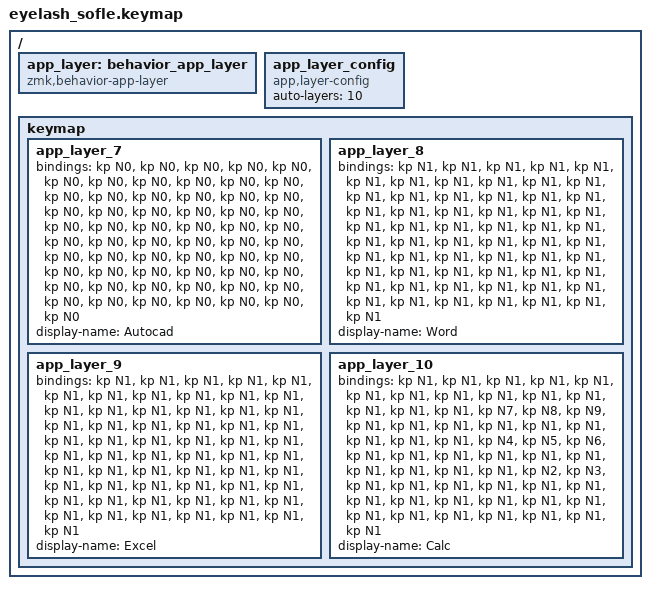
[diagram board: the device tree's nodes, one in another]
// =============================================================================
// SELENIUM KEYMAP — Main Configuration
// =============================================================================
//
// This file defines the keyboard layout using the zmk-config-selenium module.
// The SELENIUM_KEYMAP_BINDINGS macro provides a template for the base layer,
// and selenium.keymap fills in the home-row mods, layer-taps, and combos.
//
// See: https://github.com/keebs34/zmk-config-selenium/blob/main/include/selenium/settings.h
//

// =============================================================================
// LAYOUT OPTIONS (from zmk-config-selenium)
// =============================================================================

// Ergonomic column-staggered layout (Sofle/Corne style)
#define KB_LAYOUT_ERGOL

// macOS keybindings (Cmd instead of Ctrl for shortcuts)
#define MACOS

// Home-row mods: letter keys become modifiers when held
#define HT_HOME_ROW_MODS

// Shift is handled by home-row mods on E/R keys
#define HRM_SHIFT

// Pinky modifiers require holding (not tap)
#define PINKY_MOD_HOLD

// Short tapping term: 250ms to distinguish tap vs hold
#define SHORT_TAPPING_TERM 250

// =============================================================================
// BASE LAYOUT MACRO
// =============================================================================
//
// Defines all 5 rows of the keyboard:
//   Row 1 (top):       numbers, ESC, arrows, BACKSPACE
//   Row 2 (home):      LOUT1/LROW1 = outer/home keys, filled by selenium.keymap
//   Row 3 (bottom):    LOUT2/LROW2 = outer/home keys, filled by selenium.keymap
//   Row 4 (alpha low): LOUT3/LROW3 = outer/home keys, filled by selenium.keymap
//   Row 5 (thumbs):    LT1/LT2/LT3 = left thumb keys, RT1/RT2/RT3 = right thumb keys
//
// Parameters:
//   LOUT/LROW/RROW/ROUT: Injected by selenium.keymap (home-row mods, layer-taps)
//   LT1/LT2/LT3/RT3/RT2/RT1: Thumb cluster keys (layer-taps, modifiers, app_layer)
//
// &app_layer on the left thumb toggles the current app layer:
//   1 press = activate the layer stored in memory (from Mac's command)
//   2 presses = deactivate (return to base layer)
//
#define SELENIUM_KEYMAP_BINDINGS(LOUT1,  LROW1,  RROW1,  ROUT1, \
                                 LOUT2,  LROW2,  RROW2,  ROUT2, \
                                 LOUT3,  LROW3,  RROW3,  ROUT3, \
                                 LT1, LT2, LT3,  RT3, RT2, RT1) \
    &kp ESC &kp N1 &kp N2 &kp N3 &kp N4 &kp N5  &kp UP_ARROW &kp N6 &kp N7 &kp N8 &kp N9 &kp N0 &kp BACKSPACE \
    LOUT1   LROW1                               &kp DOWN_ARROW                           RROW1  ROUT1         \
    LOUT2   LROW2                               &kp LEFT_ARROW                           RROW2  ROUT2         \
    LOUT3   LROW3                               &kp RIGHT_ARROW                           RROW3  ROUT3         \
    &kp RIGHT  &none &app_layer  LT1  LT2  LT3              &none                      RT3  RT2  RT1  &none &kp UP

// Include the selenium-generated bindings
// (home-row mods, layer-taps, combos are defined here)
#include <selenium/selenium.keymap>

// =============================================================================
// CUSTOM BEHAVIOR: &app_layer (toggle app layer)
// =============================================================================
//
// Declares the &app_layer behavior node in the devicetree.
// This allows using &app_layer in the keymap bindings above.
// The behavior driver is in zmk-dongle-display/behavior_app_layer.c.
// It toggles current_app_layer (set by Mac via Raw HID) on/off.
//
/ {
    /*
     * Custom behavior node for the app layer toggle.
     * Referenced as &app_layer in the keymap bindings.
     *
     * compatible must match DT_DRV_COMPAT in behavior_app_layer.c
     * (zmk,behavior-app-layer → zmk_behavior_app_layer).
     *
     * #binding-cells = <0> means this behavior takes no parameters
     * in the keymap binding: &app_layer (no extra config needed).
     *
     * status = "okay" explicitly enables this node.
     * Although root-level nodes default to "okay" in Zephyr,
     * we set it explicitly to avoid any ambiguity with
     * DT_HAS_COMPAT_STATUS_OKAY checks in the C code.
     */
    app_layer: behavior_app_layer {
        compatible = "zmk,behavior-app-layer";
        #binding-cells = <0>;
        status = "okay";
    };
};

/ {
    // =============================================================================
    // APP LAYER CONFIGURATION (read by Selenite on Mac)
    // =============================================================================
    //
    // This node is parsed by Selenite when importing the keymap file.
    // It provides:
    //   1. Layer display names (shown in the overlay and menu bar)
    //   2. Auto-layer list (layers that activate immediately on app focus)
    //

    app_layer_config: app_layer_config {
        compatible = "app,layer-config";

        // Layers listed here activate AUTOMATICALLY when their assigned app is focused.
        // Auto mode: the layer is activated immediately by app_layer_sync.c on the dongle,
        // no need to press &app_layer.
        //
        // Layers NOT listed here are in Manual mode:
        //   The layer number is stored in memory, user activates it by pressing &app_layer.
        //
        // Example: <10> = only layer 10 (Calculator) auto-activates.
        //          Layers 7 (Autocad), 8 (Word), 9 (Excel) require manual &app_layer press.
        auto-layers = <10>;
    };

    keymap {
        // =====================================================================
        // APPLICATION LAYERS (partial overlays)
        // =====================================================================
        //
        // These layers OVERLAY on top of the base layer.
        // Only the keys defined here replace the base layer keys.
        // All other keys fall through to the base layer.
        //
        // "display-name" is the name shown in Selenite's overlay (bubble + menu bar).
        // &kp N0/N1 keys are placeholders — replace with real app-specific bindings.
        //

        // -----------------------------------------------------------------
        // Layer 7: Autocad
        // Autodesk Autocad-specific shortcuts
        // -----------------------------------------------------------------
        app_layer_7: app_layer_7 {
            bindings = <
                &kp N0 &kp N0 &kp N0 &kp N0 &kp N0 &kp N0    &kp N0 &kp N0 &kp N0 &kp N0 &kp N0 &kp N0
                &kp N0 &kp N0 &kp N0 &kp N0 &kp N0 &kp N0    &kp N0 &kp N0 &kp N0 &kp N0 &kp N0 &kp N0
                &kp N0 &kp N0 &kp N0 &kp N0 &kp N0 &kp N0    &kp N0 &kp N0 &kp N0 &kp N0 &kp N0 &kp N0
                &kp N0 &kp N0 &kp N0 &kp N0 &kp N0 &kp N0    &kp N0 &kp N0 &kp N0 &kp N0 &kp N0 &kp N0
                &kp N0 &kp N0 &kp N0 &kp N0 &kp N0 &kp N0    &kp N0 &kp N0 &kp N0 &kp N0 &kp N0 &kp N0
            >;
            display-name = "Autocad";
        };

        // -----------------------------------------------------------------
        // Layer 8: Word
        // Microsoft Word-specific shortcuts
        // -----------------------------------------------------------------
        app_layer_8: app_layer_8 {
            bindings = <
                &kp N1 &kp N1 &kp N1 &kp N1 &kp N1 &kp N1    &kp N1 &kp N1 &kp N1 &kp N1 &kp N1 &kp N1
                &kp N1 &kp N1 &kp N1 &kp N1 &kp N1 &kp N1    &kp N1 &kp N1 &kp N1 &kp N1 &kp N1 &kp N1
                &kp N1 &kp N1 &kp N1 &kp N1 &kp N1 &kp N1    &kp N1 &kp N1 &kp N1 &kp N1 &kp N1 &kp N1
                &kp N1 &kp N1 &kp N1 &kp N1 &kp N1 &kp N1    &kp N1 &kp N1 &kp N1 &kp N1 &kp N1 &kp N1
                &kp N1 &kp N1 &kp N1 &kp N1 &kp N1 &kp N1    &kp N1 &kp N1 &kp N1 &kp N1 &kp N1 &kp N1
            >;
            display-name = "Word";
        };

        // -----------------------------------------------------------------
        // Layer 9: Excel
        // Microsoft Excel-specific shortcuts
        // -----------------------------------------------------------------
        app_layer_9: app_layer_9 {
            bindings = <
                &kp N1 &kp N1 &kp N1 &kp N1 &kp N1 &kp N1    &kp N1 &kp N1 &kp N1 &kp N1 &kp N1 &kp N1
                &kp N1 &kp N1 &kp N1 &kp N1 &kp N1 &kp N1    &kp N1 &kp N1 &kp N1 &kp N1 &kp N1 &kp N1
                &kp N1 &kp N1 &kp N1 &kp N1 &kp N1 &kp N1    &kp N1 &kp N1 &kp N1 &kp N1 &kp N1 &kp N1
                &kp N1 &kp N1 &kp N1 &kp N1 &kp N1 &kp N1    &kp N1 &kp N1 &kp N1 &kp N1 &kp N1 &kp N1
                &kp N1 &kp N1 &kp N1 &kp N1 &kp N1 &kp N1    &kp N1 &kp N1 &kp N1 &kp N1 &kp N1 &kp N1
            >;
            display-name = "Excel";
        };

        // -----------------------------------------------------------------
        // Layer 10: Calculator (AUTO mode)
        // -----------------------------------------------------------------
        // This layer is listed in auto-layers, so it activates IMMEDIATELY
        // when the assigned app is focused. No need to press &app_layer.
        // Numpad layout: 7-8-9 / 4-5-6 / .-2-3
        //
        app_layer_10: app_layer_10 {
            bindings = <
                &kp N1 &kp N1 &kp N1 &kp N1 &kp N1 &kp N1    &kp N1 &kp N1 &kp N1 &kp N1 &kp N1 &kp N1
                &kp N1 &kp N1 &kp N7 &kp N8 &kp N9 &kp N1    &kp N1 &kp N1 &kp N1 &kp N1 &kp N1 &kp N1
                &kp N1 &kp N1 &kp N4 &kp N5 &kp N6 &kp N1    &kp N1 &kp N1 &kp N1 &kp N1 &kp N1 &kp N1
                &kp N1 &kp N1 &kp N1 &kp N2 &kp N3 &kp N1    &kp N1 &kp N1 &kp N1 &kp N1 &kp N1 &kp N1
                &kp N1 &kp N1 &kp N1 &kp N1 &kp N1 &kp N1    &kp N1 &kp N1 &kp N1 &kp N1 &kp N1 &kp N1
            >;
            display-name = "Calc";
        };
    };
};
